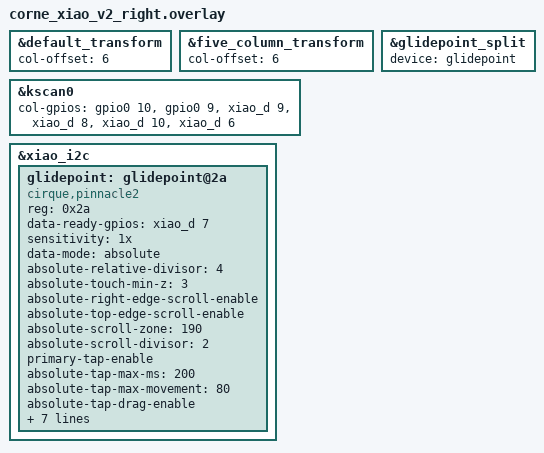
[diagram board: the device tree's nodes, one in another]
#include "corne_xiao_v2.dtsi"

&default_transform {
    col-offset = <6>;
};

&five_column_transform {
    col-offset = <6>;
};

&kscan0 {
    col-gpios
        = <&gpio0  10 GPIO_ACTIVE_HIGH>
        , <&gpio0  9  GPIO_ACTIVE_HIGH>
        , <&xiao_d 9  GPIO_ACTIVE_HIGH>
        , <&xiao_d 8  GPIO_ACTIVE_HIGH>
        , <&xiao_d 10 GPIO_ACTIVE_HIGH>
        , <&xiao_d 6  GPIO_ACTIVE_HIGH>
        ;
};

&xiao_i2c {
    status = "okay";

    glidepoint: glidepoint@2a {
        compatible = "cirque,pinnacle2";
        reg = <0x2a>;
        status = "okay";
        data-ready-gpios = <&xiao_d 7 (GPIO_ACTIVE_HIGH)>;

        sensitivity = "1x";
//        swap-xy;
//        invert-x;
        data-mode = "absolute";
        absolute-relative-divisor = <4>;
        absolute-touch-min-z = <3>;
        absolute-right-edge-scroll-enable;
        absolute-top-edge-scroll-enable;
        absolute-scroll-zone = <190>;
        absolute-scroll-divisor = <2>;
        primary-tap-enable;
        absolute-tap-max-ms = <200>;
        absolute-tap-max-movement = <80>;
        absolute-tap-drag-enable;
        absolute-tap-drag-timeout-ms = <300>;
        absolute-tap-drag-max-movement = <50>;
        absolute-secondary-tap-area-width = <250>;
        absolute-secondary-tap-area-height = <250>;
        absolute-aux-tap-area-width = <250>;
        absolute-aux-tap-area-height = <250>;   
        sleep-mode-enable;
    };
};

&glidepoint_split {
    device = <&glidepoint>;
};

// &right_encoder {
//     status = "okay";
// };
